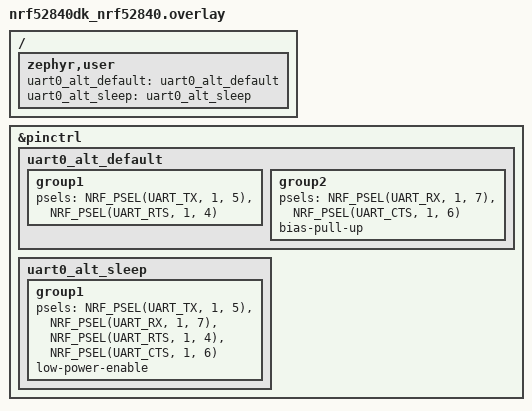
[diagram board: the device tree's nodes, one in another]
/*
 * Copyright (c) 2021 Nordic Semiconductor ASA
 * SPDX-License-Identifier: Apache-2.0
 */

/ {
	zephyr,user {
		uart0_alt_default = <&uart0_alt_default>;
		uart0_alt_sleep = <&uart0_alt_sleep>;
	};
};

&pinctrl {
	/* Alternative pin configuration for UART0 */
	uart0_alt_default: uart0_alt_default {
		group1 {
			psels = <NRF_PSEL(UART_TX, 1, 5)>,
				<NRF_PSEL(UART_RTS, 1, 4)>;
		};
		group2 {
			psels = <NRF_PSEL(UART_RX, 1, 7)>,
				<NRF_PSEL(UART_CTS, 1, 6)>;
			bias-pull-up;
		};
	};

	uart0_alt_sleep: uart0_alt_sleep {
		group1 {
			psels = <NRF_PSEL(UART_TX, 1, 5)>,
				<NRF_PSEL(UART_RX, 1, 7)>,
				<NRF_PSEL(UART_RTS, 1, 4)>,
				<NRF_PSEL(UART_CTS, 1, 6)>;
			low-power-enable;
		};
	};
};
